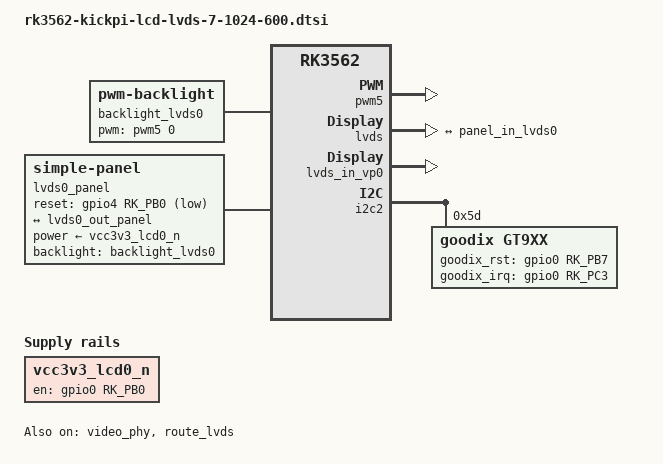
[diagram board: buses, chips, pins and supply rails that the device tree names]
#include <dt-bindings/display/media-bus-format.h>

/ {
	backlight_lvds0: backlight-lvds0 {
		compatible = "pwm-backlight";
		pwms = <&pwm5 0 25000 0>;
		brightness-levels = <
			  0  20  20  21  21  22  22  23
			 23  24  24  25  25  26  26  27
			 27  28  28  29  29  30  30  31
			 31  32  32  33  33  34  34  35
			 35  36  36  37  37  38  38  39
			 40  41  42  43  44  45  46  47
			 48  49  50  51  52  53  54  55
			 56  57  58  59  60  61  62  63
			 64  65  66  67  68  69  70  71
			 72  73  74  75  76  77  78  79
			 80  81  82  83  84  85  86  87
			 88  89  90  91  92  93  94  95
			 96  97  98  99 100 101 102 103
			104 105 106 107 108 109 110 111
			112 113 114 115 116 117 118 119
			120 121 122 123 124 125 126 127
			128 129 130 131 132 133 134 135
			136 137 138 139 140 141 142 143
			144 145 146 147 148 149 150 151
			152 153 154 155 156 157 158 159
			160 161 162 163 164 165 166 167
			168 169 170 171 172 173 174 175
			176 177 178 179 180 181 182 183
			184 185 186 187 188 189 190 191
			192 193 194 195 196 197 198 199
			200 201 202 203 204 205 206 207
			208 209 210 211 212 213 214 215
			216 217 218 219 220 221 222 223
			224 225 226 227 228 229 230 231
			232 233 234 235 236 237 238 239
			240 241 242 243 244 245 246 247
			248 249 250 251 252 253 254 255
		>;
		default-brightness-level = <200>;
	};

	vcc3v3_lcd0_n: vcc3v3-lcd0-n {
		compatible = "regulator-fixed";
		regulator-name = "vcc3v3_lcd0_n";
		regulator-boot-on;
		gpio = <&gpio0 RK_PB0 GPIO_ACTIVE_HIGH>;
		enable-active-high;
		regulator-state-mem {
			regulator-off-in-suspend;
		};
	};

	lvds0_panel: lvds0-panel {
		compatible = "simple-panel";
		power-supply = <&vcc3v3_lcd0_n>;
		backlight = <&backlight_lvds0>;
		reset-gpios = <&gpio4 RK_PB0 GPIO_ACTIVE_LOW>;

		reset-delay-ms = <320>;
		enable-delay-ms = <320>;
		prepare-delay-ms = <320>;
		init-delay-ms = <320>;
		disable-delay-ms = <20>;
		unprepare-delay-ms = <20>;
		bus-format = <MEDIA_BUS_FMT_RGB888_1X7X4_JEIDA>;

		display-timings {
			native-mode = <&timing0>;

			timing0: timing0 {
				clock-frequency = <54000000>;
				hactive = <1024>;
				vactive = <600>;
				hback-porch = <160>;
				hfront-porch = <160>;
				vback-porch = <23>;
				vfront-porch = <12>;
				hsync-len = <20>;
				vsync-len = <3>;
				hsync-active = <0>;
				vsync-active = <0>;
				de-active = <0>;
				pixelclk-active = <0>;
			};
		};
		ports {
			#address-cells = <1>;
			#size-cells = <0>;

			port@0 {
				reg = <0>;
				dual-lvds-left-pixels;
				panel_in_lvds0: endpoint {
					remote-endpoint = <&lvds0_out_panel>;
				};
			};
		};
	};
};

&pwm5 {
	status = "okay";
};

&lvds {
	status = "okay";
	ports {
		port@1 {
			reg = <1>;

			lvds0_out_panel: endpoint {
				remote-endpoint = <&panel_in_lvds0>;
			};
		};
	};
};

&dsi {
	status = "disabled";
};

&video_phy {
	status = "okay";
};

&lvds_in_vp0 {
	status = "okay";
};

&route_lvds {
	status = "okay";
	connect = <&vp0_out_lvds>;
};

&i2c2 {
	status = "okay";
	gt9xx:gt9xx@5d {
		compatible = "goodix,gt9xx";
		status = "okay";
		reg = <0x5d>;

		gtp_resolution_x = <1024>;
		gtp_resolution_y = <600>;
		gtp_int_tarigger = <1>;
		gtp_change_x2y = <0>;
		gtp_overturn_x = <0>;
		gtp_overturn_y = <0>;
		gtp_send_cfg = <0>;
		gtp_touch_wakeup = <1>;
		goodix_rst_gpio = <&gpio0 RK_PB7 GPIO_ACTIVE_HIGH>;
		goodix_irq_gpio = <&gpio0 RK_PC3 IRQ_TYPE_LEVEL_LOW>;
		pinctrl-names = "default";
		pinctrl-0 = <&touch3_gpio>;

		goodix,cfg-group0 = [
			4B 00 04 58 02 05 0D 00 01 08
			28 05 50 32 03 05 00 00 00 00
			00 00 00 00 00 00 00 8B 2A 0C
			17 15 31 0D 00 00 03 DD 03 2D
			00 00 00 00 00 00 00 00 00 00
			00 0F 41 94 C5 02 07 00 00 04
			9B 11 00 77 17 00 5C 1F 00 48
			2A 00 3B 38 00 3B 00 00 00 00
			00 00 00 00 00 00 00 00 00 00
			00 00 00 00 00 00 00 00 00 00
			00 00 00 00 00 00 00 00 00 00
			00 00 02 04 06 08 0A 0C 0E 10
			12 14 16 18 FF FF 00 00 00 00
			00 00 00 00 00 00 00 00 00 00
			00 00 00 02 04 06 08 0A 0C 0F
			10 12 13 16 18 1C 1D 1E 1F 20
			21 22 24 FF FF FF FF FF 00 00
			00 00 00 00 00 00 00 00 00 00
			00 00 00 00 91 01
		];
	};
};

&pinctrl {
	touch {
		touch3_gpio: touch-gpio {
			rockchip,pins =
				<0 RK_PC3 RK_FUNC_GPIO &pcfg_pull_none>,
				<0 RK_PB7 RK_FUNC_GPIO &pcfg_pull_none>;
		};
	};
};

